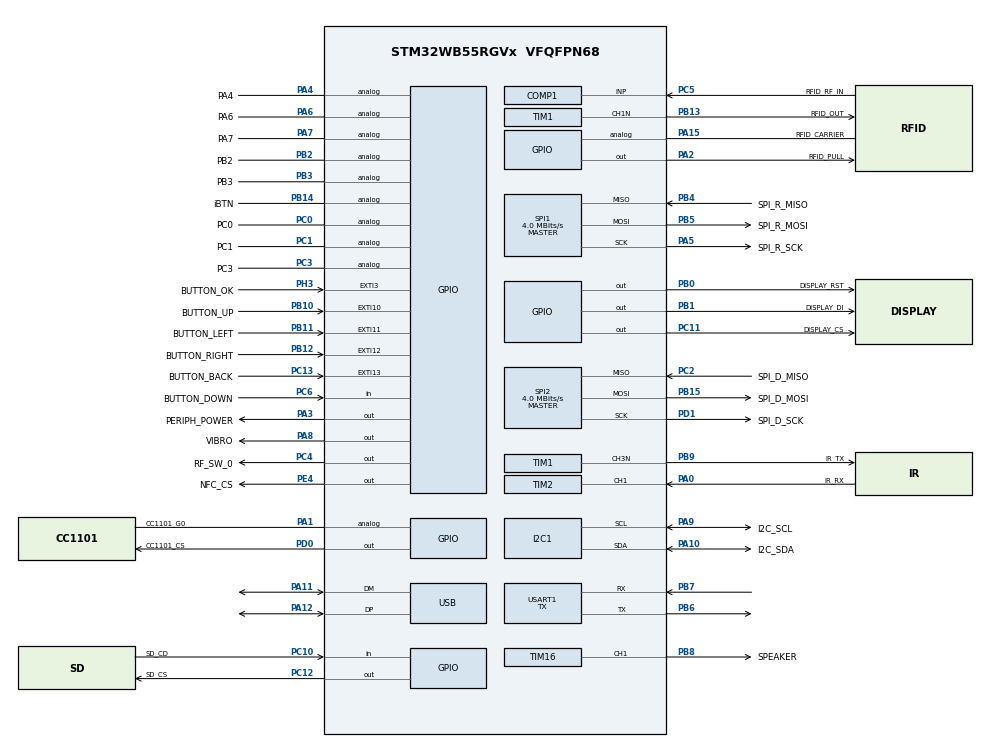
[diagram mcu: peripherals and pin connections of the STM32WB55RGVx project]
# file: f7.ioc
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ADC1.Channel-0\#ChannelRegularConversion=ADC_CHANNEL_14
ADC1.ContinuousConvMode=DISABLE
ADC1.EnableAnalogWatchDog1=false
ADC1.NbrOfConversionFlag=1
ADC1.OffsetNumber-0\#ChannelRegularConversion=ADC_OFFSET_NONE
ADC1.Rank-0\#ChannelRegularConversion=1
ADC1.SamplingTime-0\#ChannelRegularConversion=ADC_SAMPLETIME_2CYCLES_5
ADC1.master=1
COMP1.Hysteresis=COMP_HYSTERESIS_HIGH
COMP1.Mode=COMP_POWERMODE_MEDIUMSPEED
COMP1.TriggerMode=COMP_TRIGGERMODE_IT_RISING_FALLING
FREERTOS.HEAP_NUMBER=4
FREERTOS.INCLUDE_vTaskCleanUpResources=1
FREERTOS.Tasks01=app_main,24,1024,app,As weak,NULL,Dynamic,NULL,NULL
FREERTOS.configCHECK_FOR_STACK_OVERFLOW=1
FREERTOS.configENABLE_BACKWARD_COMPATIBILITY=0
FREERTOS.configENABLE_FPU=1
FREERTOS.configGENERATE_RUN_TIME_STATS=1
FREERTOS.configRECORD_STACK_HIGH_ADDRESS=1
FREERTOS.configTICK_RATE_HZ=1000
FREERTOS.configTOTAL_HEAP_SIZE=40960
FREERTOS.configUSE_IDLE_HOOK=1
FREERTOS.configUSE_TICKLESS_IDLE=2
FREERTOS.configUSE_TIMERS=1
I2C1.CustomTiming=Disabled
I2C1.I2C_Fall_Time=0
I2C1.I2C_Rise_Time=0
I2C1.Timing=0x10707DBC
Mcu.Family=STM32WB
Mcu.Name=STM32WB55RGVx
Mcu.Package=VFQFPN68
NVIC.ADC1_IRQn=true\:5\:0\:true\:false\:true\:false\:true\:true
NVIC.COMP_IRQn=true\:5\:0\:true\:false\:true\:false\:false\:true
NVIC.EXTI15_10_IRQn=true\:5\:0\:true\:false\:true\:false\:true\:true
NVIC.EXTI3_IRQn=true\:5\:0\:true\:false\:true\:false\:true\:true
NVIC.HSEM_IRQn=true\:5\:0\:true\:false\:true\:false\:false\:true
NVIC.PriorityGroup=NVIC_PRIORITYGROUP_4
NVIC.RCC_IRQn=true\:5\:0\:false\:false\:true\:true\:true\:false
NVIC.TAMP_STAMP_LSECSS_IRQn=true\:5\:0\:false\:false\:true\:true\:true\:true
NVIC.TIM1_TRG_COM_TIM17_IRQn=true\:5\:0\:false\:false\:true\:false\:false\:true
NVIC.TIM2_IRQn=true\:5\:0\:true\:false\:true\:false\:true\:true
NVIC.USB_LP_IRQn=true\:5\:0\:true\:false\:true\:false\:false\:true
OSC_IN.GPIO_Label=QUARTZ_32KHZ_IN
OSC_IN.Mode=HSE-External-Oscillator
OSC_IN.Signal=RCC_OSC_IN
OSC_OUT.GPIO_Label=QUARTZ_32KHZ_OUT
OSC_OUT.Mode=HSE-External-Oscillator
OSC_OUT.Signal=RCC_OSC_OUT
PA0.GPIO_Label=IR_RX
PA0.Signal=S_TIM2_CH1
PA1.GPIO_Label=CC1101_G0
PA1.Signal=GPIO_Analog
PA10.GPIO_Label=I2C_SDA
PA10.GPIO_Pu=GPIO_PULLUP
PA10.GPIO_Speed=GPIO_SPEED_FREQ_VERY_HIGH
PA10.Mode=I2C
PA10.Signal=I2C1_SDA
PA11.GPIO_Speed=GPIO_SPEED_FREQ_VERY_HIGH
PA11.Mode=Device
PA11.Signal=USB_DM
PA12.GPIO_Speed=GPIO_SPEED_FREQ_VERY_HIGH
PA12.Mode=Device
PA12.Signal=USB_DP
PA13.Mode=Serial_Wire
PA13.Signal=SYS_JTMS-SWDIO
PA14.Mode=Serial_Wire
PA14.Signal=SYS_JTCK-SWCLK
PA15.GPIO_Label=RFID_CARRIER
PA15.Signal=GPIO_Analog
PA2.GPIO_Label=RFID_PULL
PA2.Signal=GPIO_Output
PA3.GPIO_Label=PERIPH_POWER
PA3.GPIO_ModeDefaultOutputPP=GPIO_MODE_OUTPUT_OD
PA3.GPIO_Speed=GPIO_SPEED_FREQ_LOW
PA3.PinState=GPIO_PIN_SET
PA3.Signal=GPIO_Output
PA4.GPIO_Label=PA4
PA4.Signal=GPIO_Analog
PA5.GPIO_Label=SPI_R_SCK
PA5.Mode=Full_Duplex_Master
PA5.Signal=SPI1_SCK
PA6.GPIO_Label=PA6
PA6.Signal=GPIO_Analog
PA7.GPIO_Label=PA7
PA7.Signal=GPIO_Analog
PA8.GPIO_Label=VIBRO
PA8.Signal=GPIO_Output
PA9.GPIO_Label=I2C_SCL
PA9.GPIO_Pu=GPIO_PULLUP
PA9.GPIO_Speed=GPIO_SPEED_FREQ_VERY_HIGH
PA9.Mode=I2C
PA9.Signal=I2C1_SCL
PB0.GPIO_Label=DISPLAY_RST
PB0.Signal=GPIO_Output
PB1.GPIO_Label=DISPLAY_DI
PB1.Signal=GPIO_Output
PB10.GPIO_Label=BUTTON_UP
PB10.GPIO_ModeDefaultEXTI=GPIO_MODE_IT_RISING_FALLING
PB10.GPIO_PuPd=GPIO_PULLUP
PB10.Signal=GPXTI10
PB11.GPIO_Label=BUTTON_LEFT
PB11.GPIO_ModeDefaultEXTI=GPIO_MODE_IT_RISING_FALLING
PB11.GPIO_PuPd=GPIO_PULLUP
PB11.Signal=GPXTI11
PB12.GPIO_Label=BUTTON_RIGHT
PB12.GPIO_ModeDefaultEXTI=GPIO_MODE_IT_RISING_FALLING
PB12.GPIO_PuPd=GPIO_PULLUP
PB12.Signal=GPXTI12
PB13.GPIO_Label=RFID_OUT
PB13.Mode=Output Compare1 CH1N
PB13.Signal=TIM1_CH1N
PB14.GPIO_Label=iBTN
PB14.Signal=GPIO_Analog
PB15.GPIO_Label=SPI_D_MOSI
PB15.Mode=Full_Duplex_Master
PB15.Signal=SPI2_MOSI
PB2.GPIO_Label=PB2
PB2.Signal=GPIO_Analog
PB3.GPIO_Label=PB3
PB3.Signal=GPIO_Analog
PB4.GPIO_Label=SPI_R_MISO
PB4.Mode=Full_Duplex_Master
PB4.Signal=SPI1_MISO
PB5.GPIO_Label=SPI_R_MOSI
PB5.Mode=Full_Duplex_Master
PB5.Signal=SPI1_MOSI
PB6.Mode=Asynchronous
PB6.Signal=USART1_TX
PB7.Mode=Asynchronous
PB7.Signal=USART1_RX
PB8.GPIO_Label=SPEAKER
PB8.Signal=S_TIM16_CH1
PB9.GPIO_Label=IR_TX
PB9.Mode=PWM Generation3 CH3N
PB9.Signal=TIM1_CH3N
PC0.GPIO_Label=PC0
PC0.Signal=GPIO_Analog
PC1.GPIO_Label=PC1
PC1.Signal=GPIO_Analog
PC10.GPIO_Label=SD_CD
PC10.Signal=GPIO_Input
PC11.GPIO_Label=DISPLAY_CS
PC11.PinState=GPIO_PIN_SET
PC11.Signal=GPIO_Output
PC12.GPIO_Label=SD_CS
PC12.GPIO_Speed=GPIO_SPEED_FREQ_VERY_HIGH
PC12.PinState=GPIO_PIN_SET
PC12.Signal=GPIO_Output
PC13.GPIO_Label=BUTTON_BACK
PC13.GPIO_ModeDefaultEXTI=GPIO_MODE_IT_RISING_FALLING
PC13.GPIO_PuPd=GPIO_PULLUP
PC13.Signal=GPXTI13
PC14-OSC32_IN.GPIO_Label=QUARTZ_32MHZ_IN
PC14-OSC32_IN.Mode=LSE-External-Oscillator
PC14-OSC32_IN.Signal=RCC_OSC32_IN
PC15-OSC32_OUT.GPIO_Label=QUARTZ_32MHZ_OUT
PC15-OSC32_OUT.Mode=LSE-External-Oscillator
PC15-OSC32_OUT.Signal=RCC_OSC32_OUT
PC2.GPIO_Label=SPI_D_MISO
PC2.Mode=Full_Duplex_Master
PC2.Signal=SPI2_MISO
PC3.GPIO_Label=PC3
PC3.Signal=GPIO_Analog
PC4.GPIO_Label=RF_SW_0
PC4.Signal=GPIO_Output
PC5.GPIO_Label=RFID_RF_IN
PC5.Signal=SharedAnalog_PC5
PC6.GPIO_Label=BUTTON_DOWN
PC6.Signal=GPIO_Input
PD0.GPIO_Label=CC1101_CS
PD0.GPIO_Speed=GPIO_SPEED_FREQ_VERY_HIGH
PD0.PinState=GPIO_PIN_SET
PD0.Signal=GPIO_Output
PD1.GPIO_Label=SPI_D_SCK
PD1.Mode=Full_Duplex_Master
PD1.Signal=SPI2_SCK
PE4.GPIO_Label=NFC_CS
PE4.GPIO_Speed=GPIO_SPEED_FREQ_VERY_HIGH
PE4.PinState=GPIO_PIN_SET
PE4.Signal=GPIO_Output
PH3-BOOT0.GPIO_Label=BUTTON_OK
PH3-BOOT0.GPIO_ModeDefaultEXTI=GPIO_MODE_IT_RISING_FALLING
PH3-BOOT0.Signal=GPXTI3
ProjectManager.HeapSize=0x400
ProjectManager.StackSize=0x1000
ProjectManager.TargetToolchain=Makefile
RCC.ADCFreq_Value=48000000
RCC.AHB2CLKDivider=RCC_SYSCLK_DIV2
RCC.AHBFreq_Value=64000000
RCC.APB1Freq_Value=64000000
RCC.APB1TimFreq_Value=64000000
RCC.APB2Freq_Value=64000000
RCC.APB2TimFreq_Value=64000000
RCC.APB3Freq_Value=16000000
RCC.CortexFreq_Value=64000000
RCC.EnableCSSLSE=true
RCC.EnbaleCSS=true
RCC.HCLKFreq_Value=64000000
RCC.HSE_VALUE=32000000
RCC.HSI48_VALUE=48000000
RCC.HSI_VALUE=16000000
RCC.LPTIM1CLockSelection=RCC_LPTIM1CLKSOURCE_LSE
RCC.LSE_Drive_Capability=RCC_LSEDRIVE_MEDIUMLOW
RCC.LSE_Timout=1000
RCC.MSIOscState=DISABLED
RCC.PLLM=RCC_PLLM_DIV2
RCC.PLLSAI1N=6
RCC.PLLSourceVirtual=RCC_PLLSOURCE_HSE
RCC.PREFETCH_ENABLE=1
RCC.RFWKPClockSelection=RCC_RFWKPCLKSOURCE_LSE
RCC.RNGCLockSelection=RCC_RNGCLKSOURCE_CLK48
RCC.RTCClockSelection=RCC_RTCCLKSOURCE_LSE
RCC.SMPSCLockSelectionVirtual=RCC_SMPSCLKSOURCE_HSE
RCC.SMPSDivider=4
RCC.SYSCLKFreq_VALUE=64000000
RCC.SYSCLKSource=RCC_SYSCLKSOURCE_PLLCLK
RCC.USBFreq_Value=48000000
RCC.VCOOutputFreq_Value=128000000
RF1.Mode=RF1_Activate
RF1.Signal=RF_RF1
SH.S_TIM16_CH1.0=TIM16_CH1,PWM Generation1 CH1
SH.S_TIM2_CH1.0=TIM2_CH1,Input_Capture1_from_TI1
SH.S_TIM2_CH1.1=TIM2_CH1,Input_Capture2_from_TI1
SH.SharedAnalog_PC5.0=COMP1_INP,INP
SH.SharedAnalog_PC5.1=ADC1_IN14,IN14-Single-Ended
SPI1.BaudRatePrescaler=SPI_BAUDRATEPRESCALER_16
SPI1.CLKPhase=SPI_PHASE_2EDGE
SPI1.CalculateBaudRate=4.0 MBits/s
SPI1.DataSize=SPI_DATASIZE_8BIT
SPI1.Direction=SPI_DIRECTION_2LINES
SPI1.Mode=SPI_MODE_MASTER
SPI1.VirtualType=VM_MASTER
SPI2.BaudRatePrescaler=SPI_BAUDRATEPRESCALER_16
SPI2.CLKPhase=SPI_PHASE_1EDGE
SPI2.CalculateBaudRate=4.0 MBits/s
SPI2.DataSize=SPI_DATASIZE_8BIT
SPI2.Direction=SPI_DIRECTION_2LINES
SPI2.Mode=SPI_MODE_MASTER
SPI2.VirtualType=VM_MASTER
TIM1.Channel-Output\ Compare1\ CH1N=TIM_CHANNEL_1
TIM1.Channel-PWM\ Generation3\ CH3N=TIM_CHANNEL_3
TIM16.Channel=TIM_CHANNEL_1
TIM16.Period=291
TIM16.Prescaler=500 - 1
TIM16.Pulse=145
TIM2.AutoReloadPreload=TIM_AUTORELOAD_PRELOAD_ENABLE
TIM2.Channel-Input_Capture1_from_TI1=TIM_CHANNEL_1
TIM2.Channel-Input_Capture2_from_TI1=TIM_CHANNEL_2
TIM2.ICPolarity_CH1=TIM_INPUTCHANNELPOLARITY_FALLING
TIM2.Prescaler=64-1
USART1.AutoBaudRateEnableParam=UART_ADVFEATURE_AUTOBAUDRATE_ENABLE
USART1.Mode=MODE_TX
USART1.VirtualMode-Asynchronous=VM_ASYNC
USB_DEVICE.APP_RX_DATA_SIZE=512
USB_DEVICE.APP_TX_DATA_SIZE=512
USB_DEVICE.CLASS_NAME_FS=CDC
USB_DEVICE.MANUFACTURER_STRING=Flipper
USB_DEVICE.PRODUCT_STRING_CDC_FS=Flipper Control Virtual ComPort
USB_DEVICE.VirtualMode=Cdc
USB_DEVICE.VirtualModeFS=Cdc_FS
VP_ADC1_TempSens_Input.Mode=IN-TempSens
VP_ADC1_Vref_Input.Mode=IN-Vrefint
VP_AES1_VS_AES.Mode=AES_Activate
VP_AES2_VS_AES.Mode=AES_Activate
VP_COMP1_VS_VREFINT14.Mode=VREFINT_14
VP_CRC_VS_CRC.Mode=CRC_Activate
VP_FREERTOS_VS_CMSIS_V2.Mode=CMSIS_V2
VP_HSEM_VS_HSEM.Mode=HSEM_Activate
VP_PKA_VS_PKA.Mode=PKA_Activate
VP_RNG_VS_RNG.Mode=RNG_Activate
VP_RTC_VS_RTC_Activate.Mode=RTC_Enabled
VP_RTC_VS_RTC_Calendar.Mode=RTC_Calendar
VP_TIM16_VS_ClockSourceINT.Mode=Enable_Timer
VP_TIM1_VS_ClockSourceINT.Mode=Internal
VP_TIM2_VS_ClockSourceINT.Mode=Internal
VP_USB_DEVICE_VS_USB_DEVICE_CDC_FS.Mode=CDC_FS
board=custom

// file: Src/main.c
/* USER CODE BEGIN Header */
/**
  ******************************************************************************
  * @file           : main.c
  * @brief          : Main program body
  ******************************************************************************
  * @attention
  *
  * <h2><center>&copy; Copyright (c) 2021 STMicroelectronics.
  * All rights reserved.</center></h2>
  *
  * This software component is licensed by ST under Ultimate Liberty license
  * SLA0044, the "License"; You may not use this file except in compliance with
  * the License. You may obtain a copy of the License at:
  *                             www.st.com/SLA0044
  *
  ******************************************************************************
  */
/* USER CODE END Header */
#include "main.h"
#include "cmsis_os.h"
#include "adc.h"
#include "aes.h"
#include "comp.h"
#include "crc.h"
#include "i2c.h"
#include "pka.h"
#include "rf.h"
#include "rng.h"
#include "rtc.h"
#include "spi.h"
#include "tim.h"
#include "usart.h"
#include "usb_device.h"
#include "gpio.h"

void SystemClock_Config(void);
void MX_FREERTOS_Init(void);

int main(void) {

    /* MCU Configuration--------------------------------------------------------*/

    /* Reset of all peripherals, Initializes the Flash interface and the Systick. */
    HAL_Init();

    /* Configure the system clock */
    SystemClock_Config();

    /* Initialize all configured peripherals */
    MX_GPIO_Init();
    MX_ADC1_Init();
    MX_I2C1_Init();
    MX_RTC_Init();
    MX_SPI1_Init();
    MX_SPI2_Init();
    MX_USB_Device_Init();
    MX_TIM1_Init();
    MX_TIM2_Init();
    MX_TIM16_Init();
    MX_COMP1_Init();
    MX_RF_Init();
    MX_PKA_Init();
    MX_RNG_Init();
    MX_AES1_Init();
    MX_AES2_Init();
    MX_CRC_Init();
    MX_USART1_UART_Init();

    /* Init scheduler */
    osKernelInitialize(); /* Call init function for freertos objects (in freertos.c) */
    MX_FREERTOS_Init();
    /* Start scheduler */
    osKernelStart();

    /* We should never get here as control is now taken by the scheduler */
    /* Infinite loop */
    while(1) {

    }
}

void SystemClock_Config(void) {
    LL_FLASH_SetLatency(LL_FLASH_LATENCY_3);
    while(LL_FLASH_GetLatency() != LL_FLASH_LATENCY_3) {
    }

    /* HSE configuration and activation */
    LL_RCC_HSE_Enable();
    while(LL_RCC_HSE_IsReady() != 1) {
    }

    /* HSI configuration and activation */
    LL_RCC_HSI_Enable();
    while(LL_RCC_HSI_IsReady() != 1) {
    }

    LL_PWR_EnableBkUpAccess();
    if(LL_RCC_GetRTCClockSource() != LL_RCC_RTC_CLKSOURCE_LSE) {
        LL_RCC_ForceBackupDomainReset();
        LL_RCC_ReleaseBackupDomainReset();
    }
    LL_RCC_LSE_SetDriveCapability(LL_RCC_LSEDRIVE_MEDIUMLOW);
    LL_RCC_LSE_Enable();

    /* Wait till LSE is ready */
    while(LL_RCC_LSE_IsReady() != 1) {
    }

    LL_RCC_HSE_EnableCSS();
    LL_RCC_LSE_EnableCSS();
    /* Main PLL configuration and activation */
    LL_RCC_PLL_ConfigDomain_SYS(LL_RCC_PLLSOURCE_HSE, LL_RCC_PLLM_DIV_2, 8, LL_RCC_PLLR_DIV_2);
    LL_RCC_PLL_Enable();
    LL_RCC_PLL_EnableDomain_SYS();
    while(LL_RCC_PLL_IsReady() != 1) {
    }

    LL_RCC_PLLSAI1_ConfigDomain_48M(
        LL_RCC_PLLSOURCE_HSE, LL_RCC_PLLM_DIV_2, 6, LL_RCC_PLLSAI1Q_DIV_2);
    LL_RCC_PLLSAI1_ConfigDomain_ADC(
        LL_RCC_PLLSOURCE_HSE, LL_RCC_PLLM_DIV_2, 6, LL_RCC_PLLSAI1R_DIV_2);
    LL_RCC_PLLSAI1_Enable();
    LL_RCC_PLLSAI1_EnableDomain_48M();
    LL_RCC_PLLSAI1_EnableDomain_ADC();

    /* Wait till PLLSAI1 is ready */
    while(LL_RCC_PLLSAI1_IsReady() != 1) {
    }

    /* Sysclk activation on the main PLL */
    /* Set CPU1 prescaler*/
    LL_RCC_SetAHBPrescaler(LL_RCC_SYSCLK_DIV_1);

    /* Set CPU2 prescaler*/
    LL_C2_RCC_SetAHBPrescaler(LL_RCC_SYSCLK_DIV_2);

    LL_RCC_SetSysClkSource(LL_RCC_SYS_CLKSOURCE_PLL);
    while(LL_RCC_GetSysClkSource() != LL_RCC_SYS_CLKSOURCE_STATUS_PLL) {
    }

    /* Set AHB SHARED prescaler*/
    LL_RCC_SetAHB4Prescaler(LL_RCC_SYSCLK_DIV_1);

    /* Set APB1 prescaler*/
    LL_RCC_SetAPB1Prescaler(LL_RCC_APB1_DIV_1);

    /* Set APB2 prescaler*/
    LL_RCC_SetAPB2Prescaler(LL_RCC_APB2_DIV_1);

    /* Disable MSI */
    LL_RCC_MSI_Disable();
    while(LL_RCC_MSI_IsReady() != 0) {
    }

    /* Update CMSIS variable (which can be updated also through SystemCoreClockUpdate function) */
    LL_SetSystemCoreClock(64000000);

    /* Update the time base */
    if(HAL_InitTick(TICK_INT_PRIORITY) != HAL_OK) {
        Error_Handler();
    }
    if(LL_RCC_GetRTCClockSource() != LL_RCC_RTC_CLKSOURCE_LSE) {
        LL_RCC_SetRTCClockSource(LL_RCC_RTC_CLKSOURCE_LSE);
    }
    LL_RCC_EnableRTC();
    LL_RCC_SetUSARTClockSource(LL_RCC_USART1_CLKSOURCE_PCLK2);
    LL_RCC_SetADCClockSource(LL_RCC_ADC_CLKSOURCE_PLLSAI1);
    LL_RCC_SetI2CClockSource(LL_RCC_I2C1_CLKSOURCE_PCLK1);
    LL_RCC_SetRNGClockSource(LL_RCC_RNG_CLKSOURCE_CLK48);
    LL_RCC_SetUSBClockSource(LL_RCC_USB_CLKSOURCE_PLLSAI1);
    LL_RCC_SetCLK48ClockSource(LL_RCC_CLK48_CLKSOURCE_PLLSAI1);
    LL_RCC_SetSMPSClockSource(LL_RCC_SMPS_CLKSOURCE_HSE);
    LL_RCC_SetSMPSPrescaler(LL_RCC_SMPS_DIV_1);
    LL_RCC_SetRFWKPClockSource(LL_RCC_RFWKP_CLKSOURCE_LSE);
}

void Error_Handler(void) {
    __disable_irq();
    while(1) {
    }
}

/************************ (C) COPYRIGHT STMicroelectronics *****END OF FILE****/

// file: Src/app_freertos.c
/* USER CODE BEGIN Header */
/**
  ******************************************************************************
  * File Name          : app_freertos.c
  * Description        : Code for freertos applications
  ******************************************************************************
  * @attention
  *
  * <h2><center>&copy; Copyright (c) 2021 STMicroelectronics.
  * All rights reserved.</center></h2>
  *
  * This software component is licensed by ST under Ultimate Liberty license
  * SLA0044, the "License"; You may not use this file except in compliance with
  * the License. You may obtain a copy of the License at:
  *                             www.st.com/SLA0044
  *
  ******************************************************************************
  */
/* USER CODE END Header */

#include "FreeRTOS.h"
#include "task.h"
#include "main.h"
#include "cmsis_os.h"

/* Definitions for app_main */
osThreadId_t app_mainHandle;
const osThreadAttr_t app_main_attributes = {
    .name = "app_main",
    .priority = (osPriority_t)osPriorityNormal,
    .stack_size = 1024 * 4};

void app(void* argument);

void MX_FREERTOS_Init(void); /* (MISRA C 2004 rule 8.1) */

/* Hook prototypes */
void configureTimerForRunTimeStats(void);
unsigned long getRunTimeCounterValue(void);
void vApplicationIdleHook(void);
void vApplicationStackOverflowHook(TaskHandle_t xTask, signed char* pcTaskName);

/* USER CODE BEGIN 1 */
/* Functions needed when configGENERATE_RUN_TIME_STATS is on */
__weak void configureTimerForRunTimeStats(void) {
}

__weak unsigned long getRunTimeCounterValue(void) {
    return 0;
}
/* USER CODE END 1 */

/* USER CODE BEGIN 2 */
void vApplicationIdleHook(void) {
    /* vApplicationIdleHook() will only be called if configUSE_IDLE_HOOK is set
   to 1 in FreeRTOSConfig.h. It will be called on each iteration of the idle
   task. It is essential that code added to this hook function never attempts
   to block in any way (for example, call xQueueReceive() with a block time
   specified, or call vTaskDelay()). If the application makes use of the
   vTaskDelete() API function (as this demo application does) then it is also
   important that vApplicationIdleHook() is permitted to return to its calling
   function, because it is the responsibility of the idle task to clean up
   memory allocated by the kernel to any task that has since been deleted. */
}
/* USER CODE END 2 */

/* USER CODE BEGIN 4 */
void vApplicationStackOverflowHook(TaskHandle_t xTask, signed char* pcTaskName) {
    /* Run time stack overflow checking is performed if
   configCHECK_FOR_STACK_OVERFLOW is defined to 1 or 2. This hook function is
   called if a stack overflow is detected. */
}
/* USER CODE END 4 */

/* USER CODE BEGIN VPORT_SUPPORT_TICKS_AND_SLEEP */
__weak void vPortSuppressTicksAndSleep(TickType_t xExpectedIdleTime) {
    // Generated when configUSE_TICKLESS_IDLE == 2.
    // Function called in tasks.c (in portTASK_FUNCTION).
    // TO BE COMPLETED or TO BE REPLACED by a user one, overriding that weak one.
}
/* USER CODE END VPORT_SUPPORT_TICKS_AND_SLEEP */

void MX_FREERTOS_Init(void) {

    /* Create the thread(s) */
    /* creation of app_main */
    app_mainHandle = osThreadNew(app, NULL, &app_main_attributes);

}

__weak void app(void* argument) {
    for(;;) {
        osDelay(1);
    }
}

/************************ (C) COPYRIGHT STMicroelectronics *****END OF FILE****/
